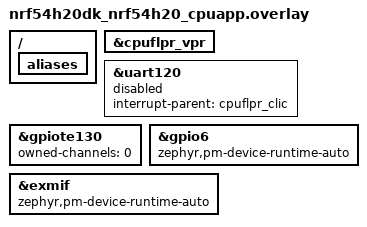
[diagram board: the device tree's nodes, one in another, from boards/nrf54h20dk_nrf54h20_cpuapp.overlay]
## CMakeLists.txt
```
#
# Copyright (c) 2026 Nordic Semiconductor ASA
#
# SPDX-License-Identifier: LicenseRef-Nordic-5-Clause
#

cmake_minimum_required(VERSION 3.20.0)

find_package(Zephyr REQUIRED HINTS $ENV{ZEPHYR_BASE})

project(idle_flpr)

target_sources(app PRIVATE src/main.c)
```

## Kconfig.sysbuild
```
#
# Copyright (c) 2026 Nordic Semiconductor ASA
#
# SPDX-License-Identifier: LicenseRef-Nordic-5-Clause
#

config SUPPORT_FLPRCORE_TESTAPP
	bool
	default y

choice FLPRCORE

config FLPRCORE_TESTAPP
	bool "testapp image"

endchoice

if !FLPRCORE_NONE

config FLPRCORE_IMAGE_NAME
	default "flpr_test_app" if FLPRCORE_TESTAPP

config FLPRCORE_IMAGE_PATH
	default "$(ZEPHYR_NRF_MODULE_DIR)/tests/benchmarks/multicore/idle_flpr/flpr_test_app" if FLPRCORE_TESTAPP

endif # !FLPRCORE_NONE

source "share/sysbuild/Kconfig"
```

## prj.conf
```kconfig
CONFIG_POWEROFF=y

CONFIG_PM_DEVICE=y
CONFIG_PM_DEVICE_RUNTIME=y

CONFIG_CONSOLE=n
CONFIG_UART_CONSOLE=n
CONFIG_SERIAL=n
CONFIG_GPIO=n
```

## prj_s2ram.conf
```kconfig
CONFIG_PM=y
CONFIG_POWEROFF=y

CONFIG_PM_DEVICE=y
CONFIG_PM_DEVICE_RUNTIME=y

CONFIG_BOOT_BANNER=n
CONFIG_NCS_BOOT_BANNER=n
CONFIG_PRINTK=n
CONFIG_LOG=n
CONFIG_CONSOLE=n
CONFIG_UART_CONSOLE=n
CONFIG_SERIAL=n

CONFIG_ASSERT=y
CONFIG_GPIO=y
```

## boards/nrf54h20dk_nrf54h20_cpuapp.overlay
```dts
/*
 * Copyright (c) 2025 Nordic Semiconductor ASA
 *
 * SPDX-License-Identifier: LicenseRef-Nordic-5-Clause
 */

&cpuflpr_vpr {
	status = "okay";
};

&uart120 {
	status = "reserved";
	interrupt-parent = <&cpuflpr_clic>;
};

/ {
	aliases {
		/delete-property/ led1;
	};
};

/delete-node/ &led1;

&gpiote130 {
	status = "okay";
	owned-channels = <0>;
};

&gpio6 {
	zephyr,pm-device-runtime-auto;
};

&exmif {
	zephyr,pm-device-runtime-auto;
};
```

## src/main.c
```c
/*
 * Copyright (c) 2026 Nordic Semiconductor ASA
 *
 * SPDX-License-Identifier: LicenseRef-Nordic-5-Clause
 */

#include <zephyr/kernel.h>

int main(void)
{
	k_sleep(K_FOREVER);

	return 0;
}
```
